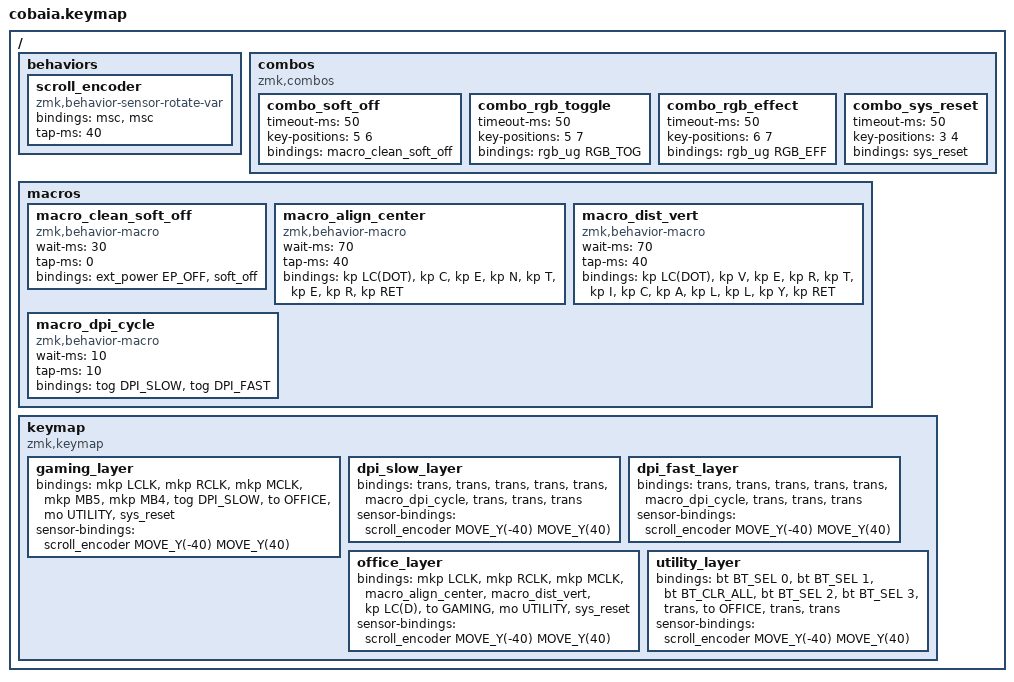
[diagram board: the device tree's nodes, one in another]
#include <behaviors.dtsi>
#include <dt-bindings/zmk/keys.h>
#include <dt-bindings/zmk/bt.h>
#include <dt-bindings/zmk/pointing.h>
#include <dt-bindings/zmk/ext_power.h>
#include <dt-bindings/zmk/rgb.h>

#define GAMING 0
#define DPI_SLOW 1
#define DPI_FAST 2
#define OFFICE 3
#define UTILITY 4

/ {
    behaviors {
    scroll_encoder: scroll_encoder {
        compatible = "zmk,behavior-sensor-rotate-var";
        #sensor-binding-cells = <2>;
        bindings = <&msc>, <&msc>;
        tap-ms = <40>;
    };
    };

    combos {
        compatible = "zmk,combos";

        combo_soft_off {
            timeout-ms = <50>;
            key-positions = <5 6>;   /* TOP_1 + TOP_2 */
            bindings = <&macro_clean_soft_off>;
        };

        combo_rgb_toggle {
            timeout-ms = <50>;
            key-positions = <5 7>;   /* TOP_1 + TOP_3 */
            bindings = <&rgb_ug RGB_TOG>;
        };

        combo_rgb_effect {
            timeout-ms = <50>;
            key-positions = <6 7>;   /* TOP_2 + TOP_3 */
            bindings = <&rgb_ug RGB_EFF>;
        };

        combo_sys_reset {
            timeout-ms = <50>;
            key-positions = <3 4>;   /* SIDE_1 + SIDE_2 */
            bindings = <&sys_reset>;
        };
    };

    macros {
        macro_clean_soft_off: macro_clean_soft_off {
            compatible = "zmk,behavior-macro";
            #binding-cells = <0>;
            wait-ms = <30>;
            tap-ms = <0>;
            bindings = <&ext_power EP_OFF>, <&soft_off>;
        };

        macro_align_center: macro_align_center {
            compatible = "zmk,behavior-macro";
            #binding-cells = <0>;
            wait-ms = <70>;
            tap-ms = <40>;
            bindings = <&kp LC(DOT)>, <&kp C>, <&kp E>, <&kp N>, <&kp T>, <&kp E>, <&kp R>, <&kp RET>;
        };

        macro_dist_vert: macro_dist_vert {
            compatible = "zmk,behavior-macro";
            #binding-cells = <0>;
            wait-ms = <70>;
            tap-ms = <40>;
            bindings = <&kp LC(DOT)>, <&kp V>, <&kp E>, <&kp R>, <&kp T>, <&kp I>, <&kp C>, <&kp A>, <&kp L>, <&kp L>, <&kp Y>, <&kp RET>;
        };

        macro_dpi_cycle: macro_dpi_cycle {
            compatible = "zmk,behavior-macro";
            #binding-cells = <0>;
            wait-ms = <10>;
            tap-ms = <10>;
            bindings = <&tog DPI_SLOW>, <&tog DPI_FAST>;
        };
    };

    keymap {
        compatible = "zmk,keymap";

        gaming_layer {
            bindings = <
                &mkp LCLK          // 0: Left Click
                &mkp RCLK          // 1: Right Click
                &mkp MCLK          // 2: Middle Click
                &mkp MB5           // 3: Side 1 (Back)
                &mkp MB4           // 4: Side 2 (Forward)
                &tog DPI_SLOW      // 5: DPI cycle enabled for Gaming
                &to OFFICE         // 6: Top 2 (Toggle Layer)
                &mo UTILITY        // 7: Top 3 (Utility Layer)
                &sys_reset         // 8: Bottom (immediate reset)
            >;
            sensor-bindings = <&scroll_encoder MOVE_Y(-40) MOVE_Y(40)>;
        };

        dpi_slow_layer {
            bindings = <
                &trans
                &trans
                &trans
                &trans
                &trans
                &macro_dpi_cycle   
                &trans
                &trans
                &trans
            >;
            sensor-bindings = <&scroll_encoder MOVE_Y(-40) MOVE_Y(40)>;
        };

        dpi_fast_layer {
            bindings = <
                &trans
                &trans
                &trans
                &trans
                &trans
                &macro_dpi_cycle
                &trans
                &trans
                &trans
            >;
            sensor-bindings = <&scroll_encoder MOVE_Y(-40) MOVE_Y(40)>;
        };

        office_layer {
            bindings = <
                &mkp LCLK
                &mkp RCLK
                &mkp MCLK
                &macro_align_center
                &macro_dist_vert
                &kp LC(D)
                &to GAMING
                &mo UTILITY
                &sys_reset
            >;
            sensor-bindings = <&scroll_encoder MOVE_Y(-40) MOVE_Y(40)>;
        };

        utility_layer {
            bindings = <
                &bt BT_SEL 0       // 0: Left     -> Force connection to PC 1
                &bt BT_SEL 1       // 1: Right    -> Force connection to PC 2
                &bt BT_CLR_ALL     // 2: Middle   -> Clear ALL slots (Full reset)
                &bt BT_SEL 2       // 3: Side 1   -> Force connection to Phone/PC 3
                &bt BT_SEL 3       // 4: Side 2   -> Force connection to PC 4
                &trans             // 5: DPI_SLOW (No change)
                &to OFFICE         // 6: OFFICE   (No change)
                &trans             // 7: (The Top 3 button itself)
                &trans             // 8: sys_reset (No change)
            >;
            sensor-bindings = <&scroll_encoder MOVE_Y(-40) MOVE_Y(40)>;
        };

    };
};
